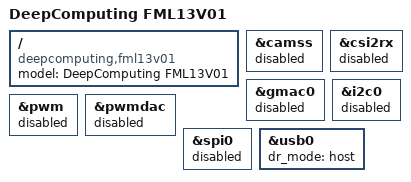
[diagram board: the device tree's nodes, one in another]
// SPDX-License-Identifier: GPL-2.0 OR MIT
/*
 * Copyright (C) 2024 DeepComputing (HK) Limited
 */

/dts-v1/;
#include "jh7110-common.dtsi"

/ {
	model = "DeepComputing FML13V01";
	compatible = "deepcomputing,fml13v01", "starfive,jh7110";
};

&camss {
	status = "disabled";
};

&csi2rx {
	status = "disabled";
};

&gmac0 {
	status = "disabled";
};

&i2c0 {
	status = "disabled";
};

&pwm {
	status = "disabled";
};

&pwmdac {
	status = "disabled";
};

&spi0 {
	status = "disabled";
};

&usb0 {
	dr_mode = "host";
};
